# MOTOR register map
Registers from a debugger description file.
Registers are 32-bit, access not given, no defined reset value unless marked. A register's access mark holds for its fields unless they carry their own. Addresses are absolute; registers are grouped by the start of their names; lines under a group give offsets from that group; [hi:lo] are bit positions; {n}, {i} and the like mark numbered series; 'fields as' and 'values as' point back to an identical list; <NAME> marks a mode.

## FORCE
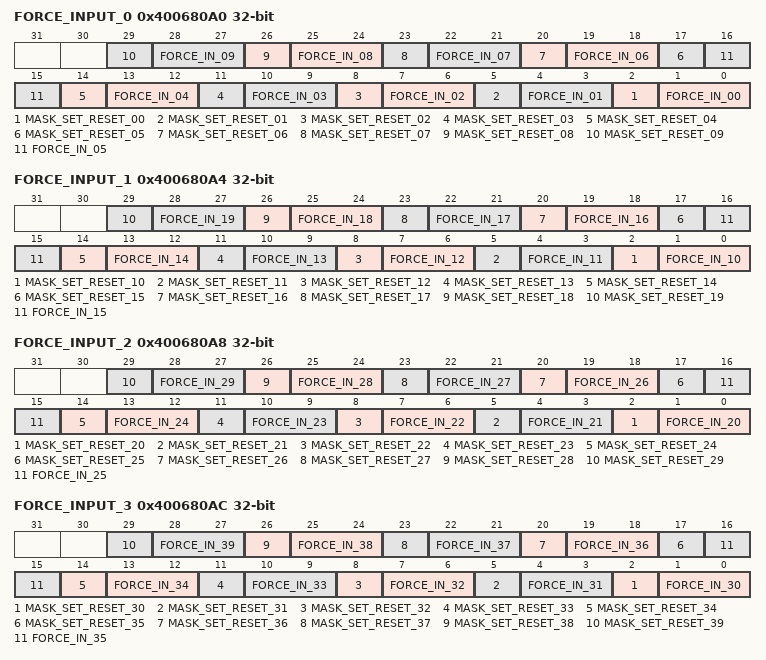
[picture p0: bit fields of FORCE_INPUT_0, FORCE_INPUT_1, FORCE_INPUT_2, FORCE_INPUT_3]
0x400680A0 FORCE_INPUT_0
  [3n+2] MASK_SET_RESET_{n:02} (n=0..9), [3n+1:3n] FORCE_IN_{n:02} (n=0..9)
0x400680A4 FORCE_INPUT_1
  [3n-28] MASK_SET_RESET_{n} (n=10..19), [3n-29:3n-30] FORCE_IN_{n} (n=10..19)
0x400680A8 FORCE_INPUT_2
  [3n-58] MASK_SET_RESET_{n} (n=20..29), [3n-59:3n-60] FORCE_IN_{n} (n=20..29)
0x400680AC FORCE_INPUT_3
  [3n-88] MASK_SET_RESET_{n} (n=30..39), [3n-89:3n-90] FORCE_IN_{n} (n=30..39)

## FAULT
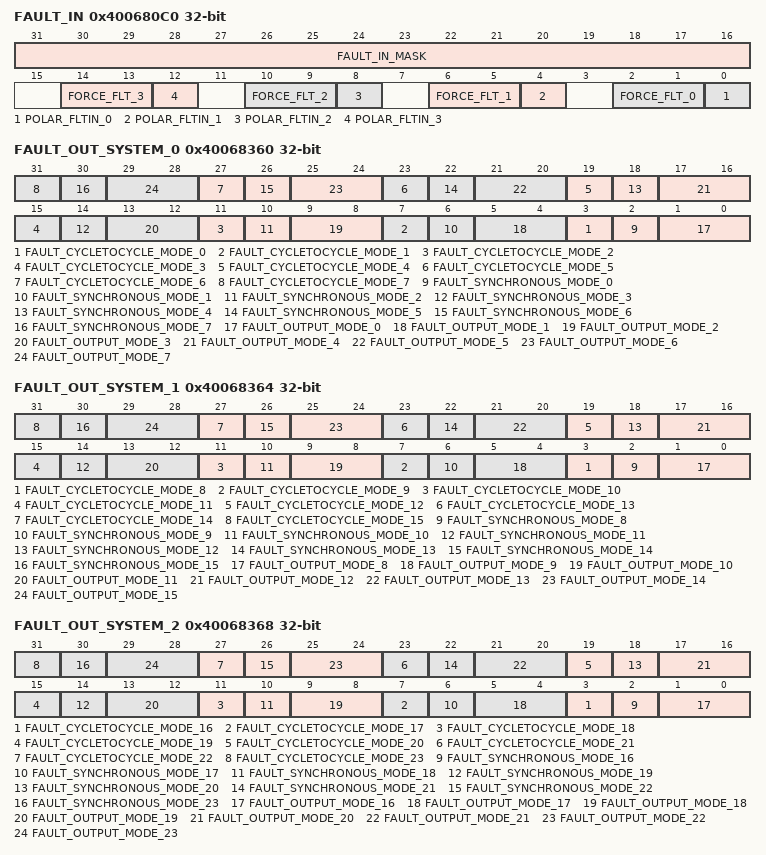
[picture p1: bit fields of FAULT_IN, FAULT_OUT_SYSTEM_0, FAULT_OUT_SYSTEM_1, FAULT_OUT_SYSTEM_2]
0x400680C0 FAULT_IN
  [31:16] FAULT_IN_MASK, [4n+2:4n+1] FORCE_FLT_{n} (n=0..3), [4n] POLAR_FLTIN_{n} (n=0..3)
0x40068360 FAULT_OUT_SYSTEM_0
  [4n+3] FAULT_CYCLETOCYCLE_MODE_{n} (n=0..7), [4n+2] FAULT_SYNCHRONOUS_MODE_{n} (n=0..7), [4n+1:4n] FAULT_OUTPUT_MODE_{n} (n=0..7)
0x40068364 FAULT_OUT_SYSTEM_1
  [4n-29] FAULT_CYCLETOCYCLE_MODE_{n} (n=8..15), [4n-30] FAULT_SYNCHRONOUS_MODE_{n} (n=8..15), [4n-31:4n-32] FAULT_OUTPUT_MODE_{n} (n=8..15)
0x40068368 FAULT_OUT_SYSTEM_2
  [4n-61] FAULT_CYCLETOCYCLE_MODE_{n} (n=16..23), [4n-62] FAULT_SYNCHRONOUS_MODE_{n} (n=16..23), [4n-63:4n-64] FAULT_OUTPUT_MODE_{n} (n=16..23)
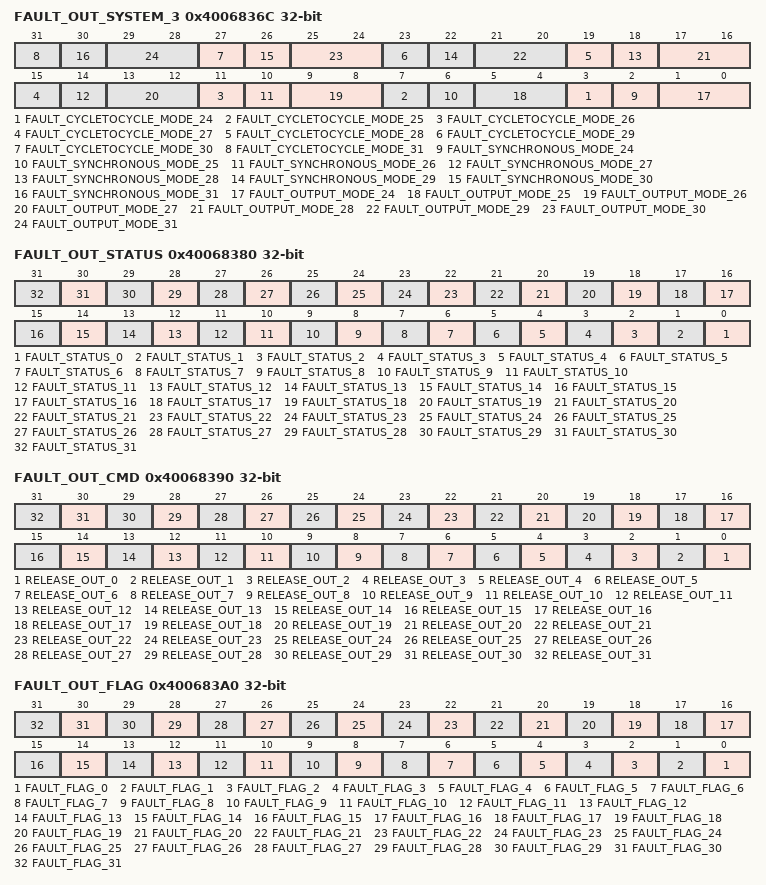
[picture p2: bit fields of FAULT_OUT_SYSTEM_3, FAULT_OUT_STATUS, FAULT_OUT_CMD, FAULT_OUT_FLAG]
0x4006836C FAULT_OUT_SYSTEM_3
  [4n-93] FAULT_CYCLETOCYCLE_MODE_{n} (n=24..31), [4n-94] FAULT_SYNCHRONOUS_MODE_{n} (n=24..31), [4n-95:4n-96] FAULT_OUTPUT_MODE_{n} (n=24..31)
0x40068380 FAULT_OUT_STATUS
  [n] FAULT_STATUS_{n} (n=0..31)
0x40068390 FAULT_OUT_CMD wo
  [n] RELEASE_OUT_{n} (n=0..31)
0x400683A0 FAULT_OUT_FLAG
  [n] FAULT_FLAG_{n} (n=0..31)

## INPUT
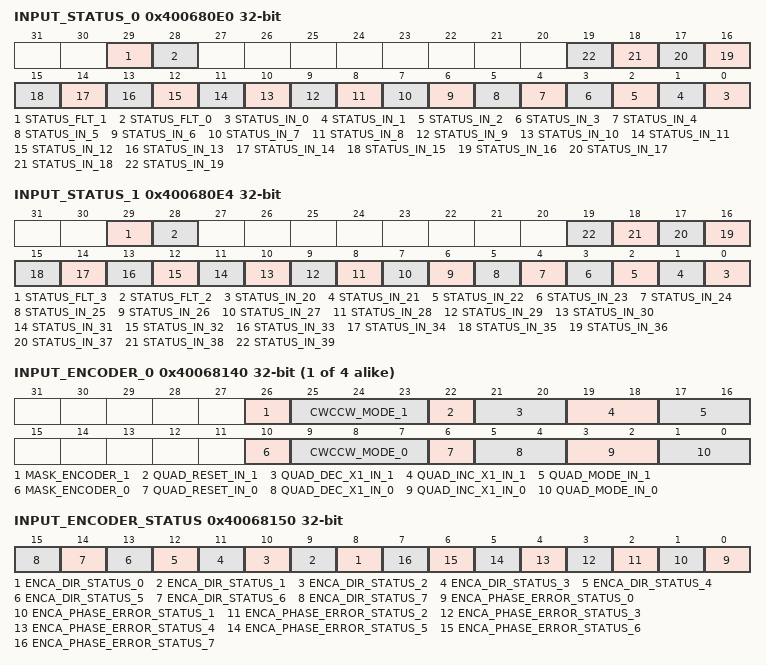
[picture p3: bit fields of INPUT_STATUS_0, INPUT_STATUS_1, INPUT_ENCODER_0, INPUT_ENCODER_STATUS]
0x400680E0 INPUT_STATUS_0 ro
  [29] STATUS_FLT_1, [28] STATUS_FLT_0, [n] STATUS_IN_{n} (n=0..19)
0x400680E4 INPUT_STATUS_1 ro
  [29] STATUS_FLT_3, [28] STATUS_FLT_2, [n-20] STATUS_IN_{n} (n=20..39)
{0x40068140+4i} INPUT_ENCODER_{i} (i=0..3)
  [26] MASK_ENCODER_{2i+1}, [25:23] CWCCW_MODE_{2i+1}, [22] QUAD_RESET_IN_{2i+1}, [21:20] QUAD_DEC_X1_IN_{2i+1}, [19:18] QUAD_INC_X1_IN_{2i+1}, [17:16] QUAD_MODE_IN_{2i+1}, [10] MASK_ENCODER_{2i}, [9:7] CWCCW_MODE_{2i}, [6] QUAD_RESET_IN_{2i}, [5:4] QUAD_DEC_X1_IN_{2i}, [3:2] QUAD_INC_X1_IN_{2i}, [1:0] QUAD_MODE_IN_{2i}
0x40068150 INPUT_ENCODER_STATUS ro
  [n+8] ENCA_DIR_STATUS_{n} (n=0..7), [n] ENCA_PHASE_ERROR_STATUS_{n} (n=0..7)
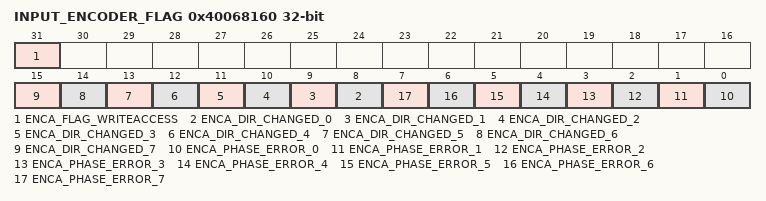
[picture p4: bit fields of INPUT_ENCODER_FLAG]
0x40068160 INPUT_ENCODER_FLAG
  [31] ENCA_FLAG_WRITEACCESS, [n+8] ENCA_DIR_CHANGED_{n} (n=0..7), [n] ENCA_PHASE_ERROR_{n} (n=0..7)

## HOMING
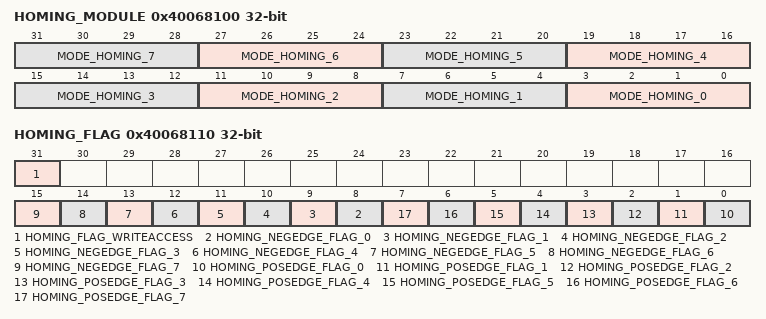
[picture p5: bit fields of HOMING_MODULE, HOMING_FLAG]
0x40068100 HOMING_MODULE
  [4n+3:4n] MODE_HOMING_{n} (n=0..7)
0x40068110 HOMING_FLAG
  [31] HOMING_FLAG_WRITEACCESS, [n+8] HOMING_NEGEDGE_FLAG_{n} (n=0..7), [n] HOMING_POSEDGE_FLAG_{n} (n=0..7)

## TRIGGER
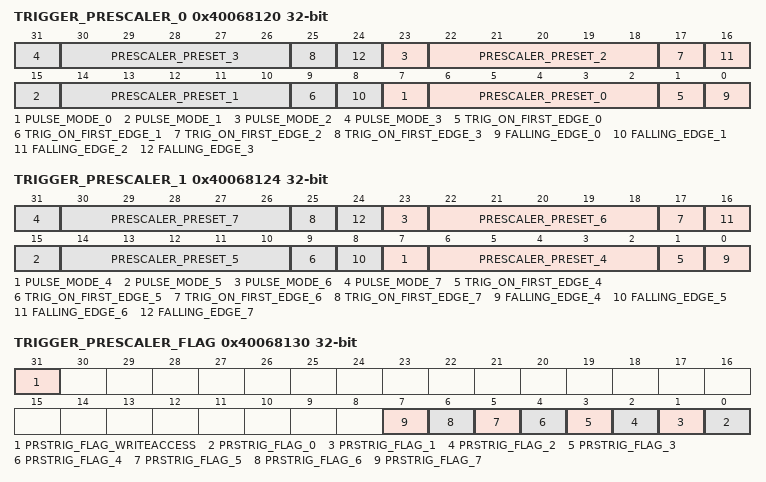
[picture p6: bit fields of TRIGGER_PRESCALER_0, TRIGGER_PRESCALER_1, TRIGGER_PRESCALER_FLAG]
0x40068120 TRIGGER_PRESCALER_0
  [8n+7] PULSE_MODE_{n} (n=0..3), [8n+6:8n+2] PRESCALER_PRESET_{n} (n=0..3), [8n+1] TRIG_ON_FIRST_EDGE_{n} (n=0..3), [8n] FALLING_EDGE_{n} (n=0..3)
0x40068124 TRIGGER_PRESCALER_1
  [8n-25] PULSE_MODE_{n} (n=4..7), [8n-26:8n-30] PRESCALER_PRESET_{n} (n=4..7), [8n-31] TRIG_ON_FIRST_EDGE_{n} (n=4..7), [8n-32] FALLING_EDGE_{n} (n=4..7)
0x40068130 TRIGGER_PRESCALER_FLAG
  [31] PRSTRIG_FLAG_WRITEACCESS, [n] PRSTRIG_FLAG_{n} (n=0..7)

## QUADRATIC
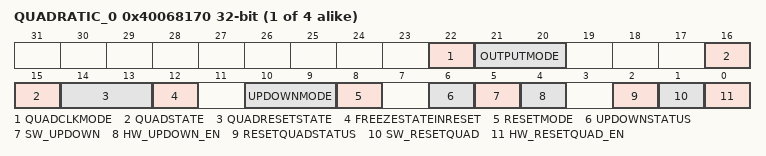
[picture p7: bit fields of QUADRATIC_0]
{0x40068170+4i} QUADRATIC_{i} (i=0..3)
  [22] QUADCLKMODE, [21:20] OUTPUTMODE, [16:15] QUADSTATE, [14:13] QUADRESETSTATE, [12] FREEZESTATEINRESET, [10:9] UPDOWNMODE, [8] RESETMODE, [6] UPDOWNSTATUS, [5] SW_UPDOWN, [4] HW_UPDOWN_EN, [2] RESETQUADSTATUS, [1] SW_RESETQUAD, [0] HW_RESETQUAD_EN
